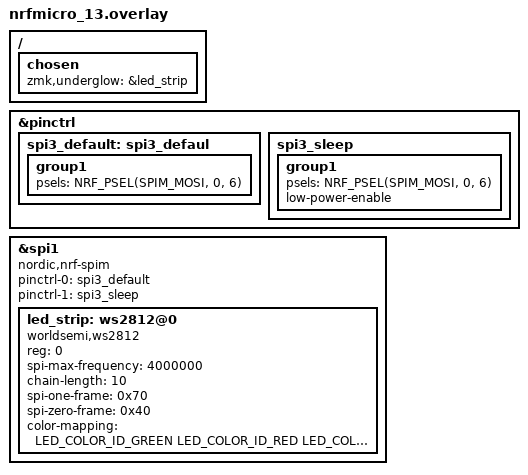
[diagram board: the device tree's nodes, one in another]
#include <dt-bindings/led/led.h>

/ {
	chosen {
		zmk,underglow = &led_strip;
	};
};

&pinctrl {
    // Keep SPI Pin Control for LED Strip (if you're using it)
    spi3_default: spi3_defaul {
        group1 {
            psels = <NRF_PSEL(SPIM_MOSI, 0, 6)>; // Assuming P0.06 for LED MOSI
        };
    };

    spi3_sleep: spi3_sleep {
        group1 {
            psels = <NRF_PSEL(SPIM_MOSI, 0, 6)>;
            low-power-enable;
        };
    };
};

//  LED strip
&spi1 {
    compatible = "nordic,nrf-spim";
    status = "okay";
    pinctrl-0 = <&spi3_default>;
    pinctrl-1 = <&spi3_sleep>;
    pinctrl-names = "default", "sleep";
    // spi-max-frequency = <4000000>; // Set the maximum SPI frequency, important for WS2812

    led_strip: ws2812@0 {
        compatible = "worldsemi,ws2812";
        /* SPI */
        reg = <0>; // Chip select (not used for single device on bus)
        spi-max-frequency = <4000000>; // 4MHz is a common frequency for WS2812

        // Chain length: adjust this to the number of LEDs in your strip
        chain-length = <10>; /* arbitrary; change at will */
        spi-one-frame = <0x70>;
        spi-zero-frame = <0x40>;

        // Color mapping (GRB is typical for WS2812)
        color-mapping = <LED_COLOR_ID_GREEN
                         LED_COLOR_ID_RED
                         LED_COLOR_ID_BLUE>;
    };
};

